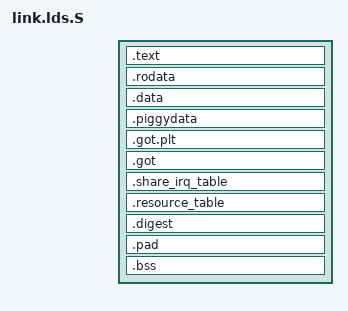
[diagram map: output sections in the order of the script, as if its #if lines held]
/*
* Copyright (c) 2019-2025 Allwinner Technology Co., Ltd. ALL rights reserved.
*
* Allwinner is a trademark of Allwinner Technology Co.,Ltd., registered in
* the the People's Republic of China and other countries.
* All Allwinner Technology Co.,Ltd. trademarks are used with permission.
*
* DISCLAIMER
* THIRD PARTY LICENCES MAY BE REQUIRED TO IMPLEMENT THE SOLUTION/PRODUCT.
* IF YOU NEED TO INTEGRATE THIRD PARTY’S TECHNOLOGY (SONY, DTS, DOLBY, AVS OR MPEGLA, ETC.)
* IN ALLWINNERS’SDK OR PRODUCTS, YOU SHALL BE SOLELY RESPONSIBLE TO OBTAIN
* ALL APPROPRIATELY REQUIRED THIRD PARTY LICENCES.
* ALLWINNER SHALL HAVE NO WARRANTY, INDEMNITY OR OTHER OBLIGATIONS WITH RESPECT TO MATTERS
* COVERED UNDER ANY REQUIRED THIRD PARTY LICENSE.
* YOU ARE SOLELY RESPONSIBLE FOR YOUR USAGE OF THIRD PARTY’S TECHNOLOGY.
*
*
* THIS SOFTWARE IS PROVIDED BY ALLWINNER"AS IS" AND TO THE MAXIMUM EXTENT
* PERMITTED BY LAW, ALLWINNER EXPRESSLY DISCLAIMS ALL WARRANTIES OF ANY KIND,
* WHETHER EXPRESS, IMPLIED OR STATUTORY, INCLUDING WITHOUT LIMITATION REGARDING
* THE TITLE, NON-INFRINGEMENT, ACCURACY, CONDITION, COMPLETENESS, PERFORMANCE
* OR MERCHANTABILITY AND FITNESS FOR A PARTICULAR PURPOSE.
* IN NO EVENT SHALL ALLWINNER BE LIABLE FOR ANY DIRECT, INDIRECT, INCIDENTAL,
* SPECIAL, EXEMPLARY, OR CONSEQUENTIAL DAMAGES (INCLUDING, BUT
* NOT LIMITED TO, PROCUREMENT OF SUBSTITUTE GOODS OR SERVICES;
* LOSS OF USE, DATA, OR PROFITS, OR BUSINESS INTERRUPTION)
* HOWEVER CAUSED AND ON ANY THEORY OF LIABILITY, WHETHER IN CONTRACT,
* STRICT LIABILITY, OR TORT (INCLUDING NEGLIGENCE OR OTHERWISE)
* ARISING IN ANY WAY OUT OF THE USE OF THIS SOFTWARE, EVEN IF ADVISED
* OF THE POSSIBILITY OF SUCH DAMAGE.
*/

OUTPUT_ARCH("riscv")
OUTPUT_FORMAT("elf32-littleriscv")
ENTRY(_start)
SECTIONS
{
  . = TEXT_START;
  . = ALIGN(4);
  _text = .;
  .text : {
    _start = .;
    *(.start)
    *(.text)
    *(.text.*)
    *(.fixup)
    *(.gnu.warning)
    *(.glue_7t)
    *(.glue_7)
  }
  .rodata : {
    *(.rodata)
    *(.rodata.*)
  }
  .data : {
    /*
     * The EFI stub always executes from RAM, and runs strictly before the
     * decompressor, so we can make an exception for its r/w data, and keep it
     */
    *(.data.efistub)
  }

  .piggydata : {
    *(.piggydata)
  }

  . = ALIGN(4);
  _etext = .;
  .got.plt : { *(.got.plt) }
  _got_start = .;
  .got : { *(.got) }
  _got_end = .;

#ifdef CONFIG_AMP_SHARE_IRQ
  .share_irq_table : {
    KEEP(*(.share_irq_table))
  }
#endif

#ifdef CONFIG_COMPONENTS_AMP
  .resource_table : {
    KEEP(*(.resource_table))
  }
#endif

    .digest : ALIGN(4)
  {
    _digest_start = ABSOLUTE(.);
    KEEP (*(.digest))
    . = ALIGN (4);
    _digest_end = ABSOLUTE(.);
  }

  /* ensure the zImage file size is always a multiple of 64 bits */
  /* (without a dummy byte, ld just ignores the empty section) */
  .pad			: { BYTE(0); . = ALIGN(8); }

  _edata = .;
  . = BSS_START;
  __bss_start = .;
  .bss : { *(.bss.*) }
  _end = .;
}
